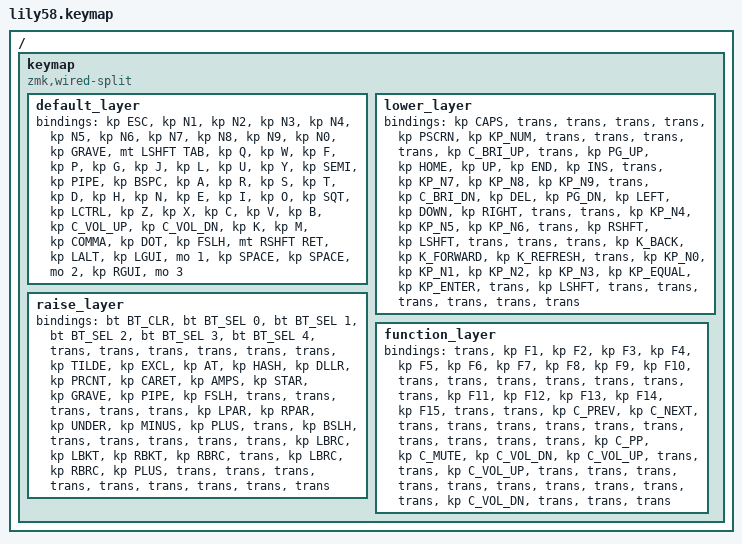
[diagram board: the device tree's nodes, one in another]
/*
 * Copyright (c) 2020 The ZMK Contributors
 *
 * SPDX-License-Identifier: MIT
 */

#include <behaviors.dtsi>
#include <dt-bindings/zmk/keys.h>
#include <dt-bindings/zmk/bt.h>
#include <dt-bindings/zmk/ext_power.h>

/ {
    keymap {
        compatible = "zmk,keymap";
        compatible = "zmk,wired-split";

        default_layer {
// -------------------------------------------------------------------------------------------------------------
// |  ESC  |  1  |  2  |   3   |   4   |   5   |                  |   6   |  7   |  8   |  9   |   0   |   `   |
// |  TAB  |  Q  |  W  |   E   |   R   |   T   |                  |   Y   |  U   |  I   |  O   |   P   |   -   |
// |  CTRL |  A  |  S  |   D   |   F   |   G   |                  |   H   |  J   |  K   |  L   |   ;   |   '   |
// | SHIFT |  Z  |  X  |   C   |   V   |   B   | PG_DN |  | PG_UP |   N   |  M   |  ,   |  .   |   /   | SHIFT |
//                     |  ALT  |  GUI  | LOWER | SPACE |  | ENTER | RAISE | BSPC |  FN  |
            bindings = <
&kp ESC    &kp N1  &kp N2  &kp N3    &kp N4    &kp N5                              &kp N6  &kp N7   &kp N8     &kp N9   &kp N0    &kp GRAVE
&mt LSHFT TAB    &kp Q   &kp W   &kp F     &kp P     &kp G                               &kp J   &kp L    &kp U      &kp Y    &kp SEMI  &kp PIPE
&kp BSPC   &kp A   &kp R   &kp S     &kp T     &kp D                               &kp H   &kp N    &kp E      &kp I    &kp O     &kp SQT
&kp LCTRL  &kp Z   &kp X   &kp C     &kp V     &kp B   &kp C_VOL_UP  &kp C_VOL_DN  &kp K   &kp M    &kp COMMA  &kp DOT  &kp FSLH  &mt RSHFT RET
                           &kp LALT  &kp LGUI  &mo 1   &kp SPACE  &kp SPACE   &mo 2   &kp RGUI  &mo 3
            >;
        };

        lower_layer {
// ------------------------------------------------------------------------------------------------------------------
// | BTCLR |  BT1  |  BT2  |  BT3  |  BT4  |  BT5  |                  |      |      |       |       |       |       |
// |       |       |       |       |       |       |                  |      |      |       |       |       |       |
// |       |       |       |       |       |       |                  |      |      |       |       |       |  "|"  |
// |       |       |       |       |       |       |       |  |       |      |      |   [   |   ]   |   =   |       |
//                         |       |       |       |       |  |  DEL  |      |      |       |
            bindings = <
&kp CAPS    &trans        &trans        &trans        &trans        &kp PSCRN                              &kp KP_NUM  &trans      &trans    &trans     &trans     &kp C_BRI_UP
&trans      &kp PG_UP     &kp HOME      &kp UP        &kp END       &kp INS                                &trans      &kp KP_N7  &kp KP_N8  &kp KP_N9  &trans     &kp C_BRI_DN
&kp DEL     &kp PG_DN     &kp LEFT      &kp DOWN      &kp RIGHT     &trans                                 &trans      &kp KP_N4  &kp KP_N5  &kp KP_N6  &trans     &kp RSHFT
&kp LSHFT   &trans        &trans        &trans        &kp K_BACK    &kp K_FORWARD &kp K_REFRESH   &trans   &kp KP_N0   &kp KP_N1  &kp KP_N2  &kp KP_N3  &kp KP_EQUAL  &kp KP_ENTER
                                        &trans        &kp LSHFT      &trans        &trans   &trans  &trans   &trans   &trans
            >;
        };

        raise_layer {
// ------------------------------------------------------------------------------------------------------------
// |      |      |      |      |      |      |                  |      |       |       |      |       |       |
// |      |      |      |      |      |      |                  |      |       |       |      |       |       |
// |      |      |      |      |      |      |                  |  <-  |   v   |   ^   |  ->  |       |   \   |
// |      |      |      |      |      |      |       |  |       |      |       |   {   |  }   |   +   |       |
//                      |      |      |      |       |  |       |      |       |       |
            bindings = <
&bt BT_CLR  &bt BT_SEL 0  &bt BT_SEL 1  &bt BT_SEL 2  &bt BT_SEL 3  &bt BT_SEL 4     &trans    &trans    &trans    &trans     &trans    &trans
&kp TILDE &kp EXCL &kp AT   &kp HASH &kp DLLR &kp PRCNT                              &kp CARET &kp AMPS  &kp STAR  &kp GRAVE  &kp PIPE  &kp FSLH
&trans    &trans   &trans   &trans   &trans   &kp LPAR                               &kp RPAR  &kp UNDER &kp MINUS &kp PLUS   &trans    &kp BSLH
&trans    &trans   &trans   &trans   &trans   &kp LBRC   &kp LBKT          &kp RBKT  &kp RBRC  &trans    &kp LBRC  &kp RBRC   &kp PLUS  &trans
                           &trans   &trans   &trans   &trans                   &trans   &trans    &trans    &trans
            >;
        };

        function_layer {
// ------------------------------------------------------------------------------------------------------------
// |      |  F1  |  F2  |  F3  |  F4  |  F5  |                  |  F6   |  F7   |  F8  |  F9  |  F10  |       |
// |      |      |      |      |      |      |                  |  F11  |  F12  |      |      | PSCRN |       |
// |      | PREV | NEXT |      |      |      |                  |       |       |      |      |       |       |
// |      | PLAY | MUTE | VOL- | VOL+ |      |       |  |       |       |       |      |      |       |       |
//                      |      |      |      |       |  |       |       |       |      |
            bindings = <
&trans   &kp F1      &kp F2      &kp F3        &kp F4        &kp F5                     &kp F6   &kp F7   &kp F8   &kp F9   &kp F10    &trans
&trans   &trans      &trans      &trans        &trans        &trans                     &kp F11  &kp F12  &kp F13  &kp F14  &kp F15    &trans
&trans   &kp C_PREV  &kp C_NEXT  &trans        &trans        &trans                     &trans   &trans   &trans   &trans   &trans     &trans
&trans   &kp C_PP    &kp C_MUTE  &kp C_VOL_DN  &kp C_VOL_UP  &trans   &trans   &kp C_VOL_UP   &trans   &trans   &trans   &trans   &trans     &trans
                                 &trans        &trans        &trans   &trans   &kp C_VOL_DN   &trans   &trans   &trans
            >;
        };
    };
};
